# H6 register map
Vendor: Allwinner; Series: H6; File version: 0.1
CPU: CA53 0, little endian, MPU, no FPU, 0 interrupt priority bits
Registers are 32-bit, read-write, reset 0x0 unless marked. A register's access mark holds for its fields unless they carry their own. Offsets are from the block's base; [hi:lo] are bit positions; <NAME> marks a mode.

## R_OWC
Base 0x07040400
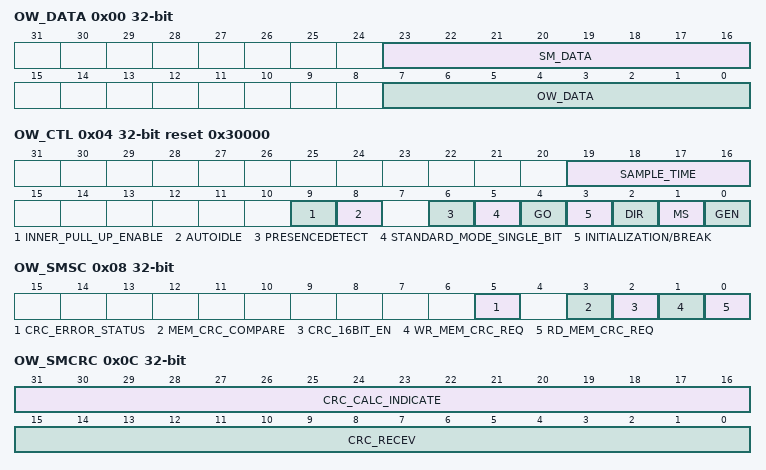
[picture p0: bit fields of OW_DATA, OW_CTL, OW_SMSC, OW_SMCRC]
0x00 OW_DATA — One Wire Data Register
  [23:16] SM_DATA — These fields are for Simple Mode data send or receive in a one wire transmission. After this byte data transfer finishing, a transmission complete interrupt will generate.
  [7:0] OW_DATA — Data byte for transmitting or received In Simple Mode mode, these fields are for the command byte transmission. When GO bit is set (the INITIALIZATION/BREAK bit is not set at the same time), these fields will be sent as the address and command for a Simple Mode transfer. After the command byte transmission finished, the controller in Simple Mode will send next 8 bit data from SM_DATA when the DIR bit is 1 or receive one byte data to SM_DATA when the DIR bit is 0. In Standard Mode, if the INITIALIZATION/BREAK bit is not set, the controller samples/sends data to/from these fields determining by the DIR bit when the Go bit is set. When the ONE_WIRE_SINGLE_BIT is enabled, only the first bit of these fields is available.
0x04 OW_CTL reset 0x30000 — One Wire Control Register
  [19:16] SAMPLE_TIME — These fields determine the sample times in digital circuit.
  [9] INNER_PULL_UP_ENABLE — When this bit is set, the inner pull up for one wire bus is determined by inner output (pull up is off when bus is drive 0) 0: inner pull up is on 1: inner pull up is off when bus is drive 0
    0=on (inner pull up is on); 1=off (inner pull up is off when bus is drive 0)
  [8] AUTOIDLE — Auto Idle 0: Module clock is free-running 1: Module clock is in power saving mode: the function clock is running only when module is accessed or inside logic is in function to process events.
    0=free_minus_running (Module clock is free-running); 1=in (Module clock is in power saving mode: the function clock is running only when module is accessed or inside logic is in function to process events.)
  [6] PRESENCEDETECT ro — Slave Presence Indicator This read-only flag is only used in Standard Mode The value of this field indicates whether there is Presence Pulse responding to the host initialization pulse. The flag is updated when the OW_INT_STATUS[0] Presence Detect Interrupt Flag is set.
  [5] STANDARD_MODE_SINGLE_BIT — The single-bit mode is only supported for Standard Mode. After the bit is transferred, Tx-complete or Rx-complete interrupt will generate for corresponding transfer operation. 0: Disabled 1: Enabled
    0=Disabled; 1=Enabled
  [4] GO — Go Go Bit Write 1 to start the appropriate operation. If the INITIALIZATION/BREAK bit is set, the controller generates the initialization or break pulse. If the INITIALIZATION/BREAK bit is not set, the controller in Standard Mode samples/sends data to/from the OW_DATA fields determining by the DIR bit, or controller in Simple Mode begins a transfer sequence with the command byte in OW_DATA. Bit returns to 0 after the operation is complete.
  [3] INITIALIZATION/BREAK — Initialization/Break Bit Write 1 to send initialization pulse for the Standard Mode or break pulse for the Simple Mode. The OW_DATA register will be flushed when initialization or the break situation is generating. Bit returns to 0 after pulse is sent. The pulse generates after the Go bit is set.
  [2] DIR — Direction Bit In Standard Mode, this field determines if next operation (byte operation or bit operation) is read or write. In Simple Mode, this field determines if the current transfer sequence is read or write. 0 = read 1 = write The operation starts after the Go bit is set.
  [1] MS — Mode Selection Bit 0: Standard Mode 1: Simple Mode
    0=Standard Mode; 1=Simple Mode
  [0] GEN — Global Enable This field is used to enable or disable the One Wire Controller. A disable on this bit overrides any other block or channel enables and flushes all FIFOs. 0: Disable 1: Enable
    0=Disable; 1=Enable
0x08 OW_SMSC — One Wire Standard Mode Special Control Register
  [5] CRC_ERROR_STATUS — These fields indicate the result of the CRC comparing. 0: CRC comparing right 1: CRC comparing wrong
    0=CRC_comparing_right; 1=CRC_comparing_wrong
  [3] MEM_CRC_COMPARE — This field is only used in Standard Mode. When this field is set, the controller will compare the value in the CRC_RECEV field with the data read from the CRC_CALC_INDICATE field, and then returns corresponding result in the CRC_ERROR_STATUS field and generates CRC finish interrupt. The CRC shift register and CRC_CALC_INDICATE field will be cleaned to 0 then. This field will be automatically cleaned when the CRC compare is finish.
  [2] CRC_16BIT_EN — This field is only used in Standard Mode. and is set to 1 to select 16bit CRC, else the 8bit CRC is select. 0: CRC_8BIT_EN 1: CRC_16BIT_EN
    0=CRC_8BIT_EN; 1=CRC_16BIT_EN
  [1] WR_MEM_CRC_REQ — This field is only used in One Wire mode. When this bit is set, the bit send to the device will be took into calculate the CRC value (CRC8 or CRC16). The calculation will stop when this bit is cleaned. The value will be preserved in the corresponding CRC (CRC8 or CRC16) shift register then.
  [0] RD_MEM_CRC_REQ — This field is only used in Standard Mode. When this bit is set, the bit received from the device will be took into calculate the CRC value (CRC8 or CRC16). The calculation will stop when this bit is cleaned. The value will be preserved in the corresponding CRC (CRC8 or CRC16) shift register then.
0x0C OW_SMCRC — One Wire Standard Mode CRC Register
  [31:16] CRC_CALC_INDICATE ro — This field indicates the CRC value calculated by the CRC shift register.
  [15:0] CRC_RECEV — The data CRC value (CRC8 or CRC16) will be written to these fields by software for CRC comparing.
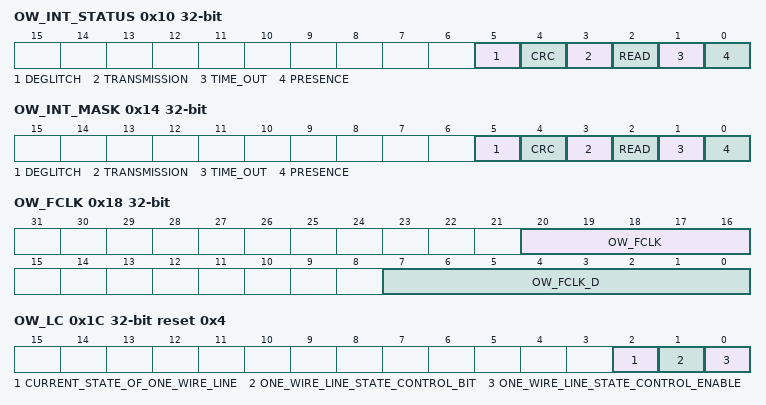
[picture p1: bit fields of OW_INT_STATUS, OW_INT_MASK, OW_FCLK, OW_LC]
0x10 OW_INT_STATUS — One Wire Interrupt Status Register
  [5] DEGLITCH write-1-clears — Deglitch Detected Interrupt Flag This flag indicates a deglitch in the bus. The controller looks for any glitch in the sample window for at least 1us. If the Deglitch Interrupt is enabled, an interrupt will issue when any deglitch occurs in the bus. The interrupt condition is cleared by writing `1` to this field.
  [4] CRC write-1-clears — Comparing Complete Interrupt Flag This flag is used in Standard Mode., and is used to indicate the CRC comparing has finished. The interrupt condition is cleared by writing `1` to this field.
  [3] TRANSMISSION write-1-clears — Transmission Complete Interrupt Flag In Standard Mode., the flag is set when a write operation of one byte or one bit in single-bit mode was completed. The interrupt is generated then. In Simple Mode., the flag is set when a write operation of one byte was completed. The interrupt is also generated. The interrupt condition is cleared by writing `1` to this field.
  [2] READ write-1-clears — Read Complete Interrupt Flag In Standard Mode., the flag is set when a byte or a bit in single-bit mode has been successfully read. The interrupt is generated then. In Simple Mode. the flag is set when a byte has been successfully read. The interrupt is also generated then. The interrupt condition is cleared by writing `1` to this field.
  [1] TIME_OUT write-1-clears — Time-out Interrupt Flag This flag is only used in Simple Mode. The flag is set when two event happened. The one event is that after a read command initiated by the host, the slave did not pull the line low within the specified time (512 us). The other event is that another bit transfer does not begin after a specified time (512 us) from the pre-bit beginning. When the above situation occurs, the interrupt generates and the value of this field is set. The interrupt condition is cleared by writing `1` to this field.
  [0] PRESENCE write-1-clears — Presence Detect Interrupt Flag In Standard Mode., this interrupt status is set when the Initialization Pulse is completed. The interrupt is generated then and the PRESENCEDETECT bit is update. In Simple Mode., the flag is set when the successful completion of a break pulse. The interrupt is also generated then. The interrupt condition is cleared by writing `1` to this field.
0x14 OW_INT_MASK — One Wire Interrupt Mask Register
  [all] fields
    0=Disable; 1=Enable
  [5] DEGLITCH — Deglitch Detected Interrupt Enable 0: Disable 1: Enable
  [4] CRC — Comparing Complete Interrupt Enable 0: Disable 1: Enable
  [3] TRANSMISSION — Transmission Complete Interrupt Enable 0: Disable 1: Enable
  [2] READ — Read Complete Interrupt Enable 0: Disable 1: Enable
  [1] TIME_OUT — Time-out Interrupt Enable 0: Disable 1: Enable
  [0] PRESENCE — Presence Detect Interrupt Enable 0: Disable 1: Enable
0x18 OW_FCLK — One Wire Function Clock Register
  [20:16] OW_FCLK — (n) n-MHz clock is needed to use as a time reference by the machine. Transitions between the states of the state machine as well as actions triggered at precise time deadlines are expressed using the n - MHz clock.
  [7:0] OW_FCLK_D — OW_FCLK = SOURCE_CLK/OW_FCLK_D
0x1C OW_LC reset 0x4 — One Wire Line Control Register
  [2] CURRENT_STATE_OF_ONE_WIRE_LINE ro — Current state of One Wire Line 0: low 1: high
    0=low; 1=high
  [1] ONE_WIRE_LINE_STATE_CONTROL_BIT — One Wire line state control bit When the line control mode is enabled (bit [0] set), value of this bit decides the output level of the One Wire line. 0: output low level 1: output high level
    0=output_low_level; 1=output_high_level
  [0] ONE_WIRE_LINE_STATE_CONTROL_ENABLE — One Wire line state control enable When this bit is set, the state of One Wire line is control by the value of bit [1]. 0: disable line control mode 1: enable line control mode
    0=disable line control mode; 1=enable line control mode
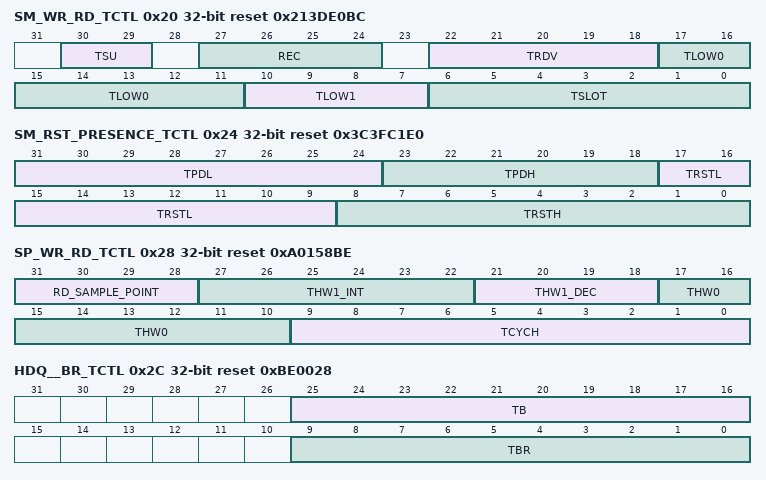
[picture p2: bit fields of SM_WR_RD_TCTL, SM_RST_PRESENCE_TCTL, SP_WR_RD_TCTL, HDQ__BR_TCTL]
0x20 SM_WR_RD_TCTL reset 0x213DE0BC — Standard Mode Write Read Timing Control Register
  [30:29] TSU — Read Data Setup. In standard speed, range: t(SU) < 1 00: 0.5us 01: 1us 10: 2us 11: 4us
    0=_0_point_5us (0.5us); 1=_1us; 2=_2us; 3=_4us
  [27:24] REC — Recovery Time, t(recovery) = N us. In standard speed, range: 1us <= t(recovery)
  [22:18] TRDV — Read data valid time, t(rdv) = N us. In standard speed, range: Exactly 15
  [17:11] TLOW0 — Write Zero time Low, Tlow0 = N us. The range setting for TLOW0 is from 0x3c to 0x77. In standard mode, range:60<= t(low0) < t(tslot) <120
  [10:7] TLOW1 — Write One time Low, or TLOWR both are same. t(low1) = N us. The range setting for TLOW1 and TLOWR here is from 0x1 to 0xf. In standard speed, range:1 <= t(low1) < 15. t(lowR) = N owr clks. In standard speed, rang = 1 <= t(lowR) <15
  [6:0] TSLOT — Active time slot for write and read data, t(slot) = N us. The range setting for TSLOT is from 0x3c to 0x78. In standard mode, range:60 <= t(slot) <120
0x24 SM_RST_PRESENCE_TCTL reset 0x3C3FC1E0 — Standard Mode Reset Presence Timing Control Register
  [31:24] TPDL — PRESENCE_DETECT_LOW t(pdl) = N us. The range setting for TPDL in these fields is from 0 to 0xf0. In standard speed, Range: 60 <= t(pdl) <240.
  [23:18] TPDH — PRESENCE_DETECT_HIGH t(pdh) = N us. The range setting for TPDH in these fields is from 0xf to 0x3c. In standard speed, range: 15 <= t(pdh) < 60 .
  [17:9] TRSTL — RESET_TIME_LOW t(rstl) = N us. The range setting for TRSTL in these fields is from 0 to 0xff. In standard speed, Range: 480 <= t(rstl) < infinity
  [8:0] TRSTH — RESET_TIME_HIGH, t(rsth) = N us. The range setting for TRSTH in these fields is from 0 to 0xff. In standard speed, Range : 480 <= t(rsth) < infinity
0x28 SP_WR_RD_TCTL reset 0xA0158BE — Simple Mode Timing Control Register
  [31:28] RD_SAMPLE_POINT — When controller of the Simple Mode read, the default sample point is at the middle of the THW1 point and the THW0 point, named S(middle). When these fields are set, the corresponding new sample point will be determined. 0000 S(middle) 1000 S(middle)-30us 0001 S(middle)+5us 1001 S(middle)+40us 0010 S(middle)-5us 1010 S(middle)-40us 0011 S(middle)+10us 1011 S(middle)+50us 0100 S(middle)-10us 1100 S(middle)-50us 0101 S(middle)+20us 1101 S(middle)+60us 0110 S(middle)-20us 1110 S(middle)-60us 0111 S(middle)+30us 1111 reserve
  [27:22] THW1_INT — t(HW1_INT) = N us. The range setting for THW1_INT in these fields is from 0 to 0x3f, which is the integer part of the THW1. In HDQ mode, Range: t(HW0) <= 50 us.
  [21:18] THW1_DEC — THW1_DEC is the decimal part of the THW1. t(HW1_DEC) = N ow_clks. The value for the THW1 = THW1_INT + THW1_DEC.
  [17:10] THW0 — t(HW0) = N us. The range setting for THW0 in these fields is from 0 to 0xff. In HDQ mode, Range: t(HW0) <= 145 us.
  [9:0] TCYCH — t(CYCH) = N us. The range setting for TCYCH in these fields is from 0 to 0x3ff. In HDQ mode, Rang: 190 us <= t(CYCH) <= infinity.
0x2C HDQ__BR_TCTL reset 0xBE0028
  [25:16] TB — t(B) = N us. The range setting for TB in these fields is from 0 to 0x 3ff. In HDQ mode, Rang: 190 us <= t(B) <= infinity.
  [9:0] TBR — t(BR) = N us. The range setting for TBR in these fields is from 0 to 0xff. In HDQ mode, Rang: 40 us <= t(BR) <= infinity.
